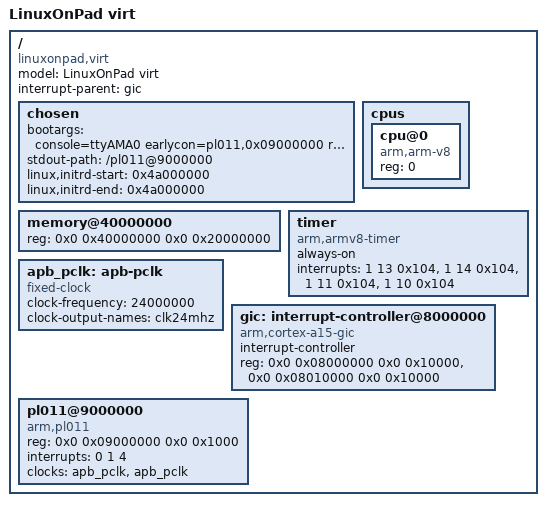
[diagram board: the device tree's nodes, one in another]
/dts-v1/;

/*
 * Device tree for the LinuxOnPad virtual board (modelled on QEMU "virt").
 * Compile with:  dtc -I dts -O dtb -o build/lop-virt.dtb dts/lop-virt.dts   (or `make dtb`)
 *
 * Engine support today: RAM and the PL011 UART only. The GIC and the generic timer
 * nodes are here because Linux needs them to boot fully, but the engine does not
 * emulate them yet, so a real kernel will stall at interrupt-controller / timer setup.
 * `earlycon` output works without them.
 *
 * If you change the RAM size passed to the engine (--ram MB), update memory@40000000 too.
 * linux,initrd-start/end are placeholders: the engine patches them when --initrd is given.
 */
/ {
	compatible = "linuxonpad,virt";
	model = "LinuxOnPad virt";
	#address-cells = <2>;
	#size-cells = <2>;
	interrupt-parent = <&gic>;

	chosen {
		bootargs = "console=ttyAMA0 earlycon=pl011,0x09000000 rdinit=/init";
		stdout-path = "/pl011@9000000";
		linux,initrd-start = /bits/ 64 <0x4a000000>;
		linux,initrd-end = /bits/ 64 <0x4a000000>;
	};

	memory@40000000 {
		device_type = "memory";
		reg = <0x0 0x40000000 0x0 0x20000000>; /* 512 MiB */
	};

	cpus {
		#address-cells = <1>;
		#size-cells = <0>;

		cpu@0 {
			device_type = "cpu";
			compatible = "arm,arm-v8";
			reg = <0>;
		};
	};

	timer {
		compatible = "arm,armv8-timer";
		always-on;
		interrupts = <1 13 0x104>, <1 14 0x104>, <1 11 0x104>, <1 10 0x104>;
	};

	apb_pclk: apb-pclk {
		compatible = "fixed-clock";
		#clock-cells = <0>;
		clock-frequency = <24000000>;
		clock-output-names = "clk24mhz";
	};

	gic: interrupt-controller@8000000 {
		compatible = "arm,cortex-a15-gic";
		#interrupt-cells = <3>;
		interrupt-controller;
		reg = <0x0 0x08000000 0x0 0x10000>,
		      <0x0 0x08010000 0x0 0x10000>;
	};

	pl011@9000000 {
		compatible = "arm,pl011", "arm,primecell";
		reg = <0x0 0x09000000 0x0 0x1000>;
		interrupts = <0 1 4>;
		clocks = <&apb_pclk>, <&apb_pclk>;
		clock-names = "uartclk", "apb_pclk";
	};
};
